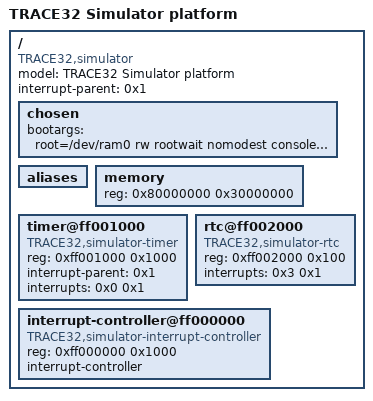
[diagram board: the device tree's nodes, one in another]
/dts-v1/;

/ {
	#address-cells = <0x1>;
	#size-cells = <0x1>;
	model = "TRACE32 Simulator platform";
	compatible = "TRACE32,simulator";
	interrupt-parent = <0x1>;

	chosen {
		bootargs = "root=/dev/ram0 rw rootwait nomodest console=hvc initrd=0xA0000000,8M";
	};

	aliases {
	};

	memory {
		device_type = "memory";
		reg = <0x80000000 0x30000000>;
	};

	timer@ff001000 {
		compatible = "TRACE32,simulator-timer";
		reg = <0xff001000 0x1000>;
		interrupt-parent = <0x1>;
		interrupts = <0x0 0x1>;
	};

	rtc@ff002000 {
		compatible = "TRACE32,simulator-rtc";
		reg = <0xff002000 0x100>;
		interrupts = <0x3 0x1>;
	};

	interrupt-controller@ff000000 {
		compatible = "TRACE32,simulator-interrupt-controller";
		reg = <0xff000000 0x1000>;
		interrupt-controller;
		#interrupt-cells = <0x2>;
		linux,phandle = <0x1>;
		phandle = <0x1>;
	};
};
